# YC3122 register map
Series: ARMCM0; File version: 1.0
CPU: CM0 r1p0, little endian, no MPU, no FPU, 8 interrupt priority bits
Registers are 32-bit, read-write, reset 0x0 unless marked. A register's access mark holds for its fields unless they carry their own. Offsets are from the block's base; [hi:lo] are bit positions; {n}, {i} and the like mark numbered series; 'fields as' and 'values as' point back to an identical list.

## MISO7811
Base 0x000F8F00; alternate view of MDMA_7811
0x00 BASE_ADDR_T1
  [19:0] ISO_BASE_ADDR — Character write base add ress for track 1
0x04 BASE_ADDR_T2
  [19:0] ISO_BASE_ADDR — Character write base add ress for track 2
0x08 BASE_ADDR_T3
  [19:0] ISO_BASE_ADDR — Character write base add ress for track 3
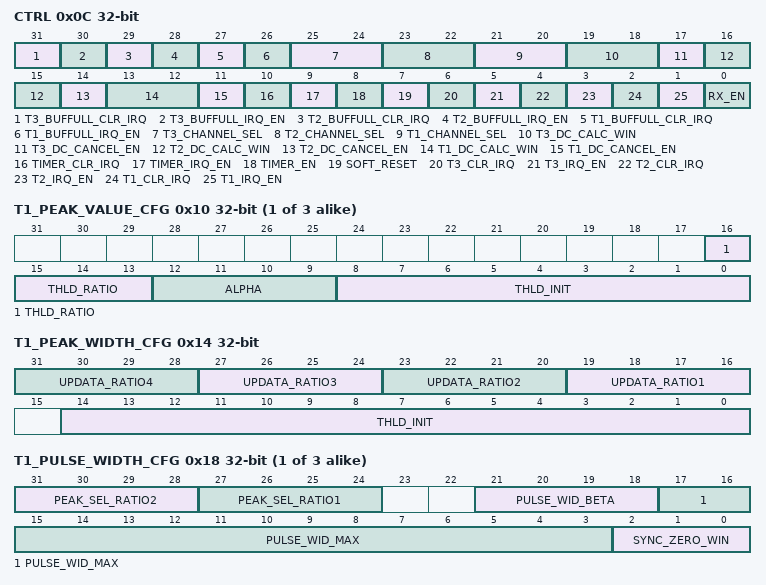
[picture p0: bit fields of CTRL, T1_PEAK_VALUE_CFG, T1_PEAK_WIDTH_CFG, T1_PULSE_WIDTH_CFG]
0x0C CTRL
  [31] T3_BUFFULL_CLR_IRQ — Clear 7811 track 3 buffe r full interrupt
  [30] T3_BUFFULL_IRQ_EN — 7811 track 3 buffer full interrupt enable
  [29] T2_BUFFULL_CLR_IRQ — Clear 7811 track 2 buffe r full interrupt
  [28] T2_BUFFULL_IRQ_EN — 7811 track 2 buffer full interrupt enable
  [27] T1_BUFFULL_CLR_IRQ — Clear 7811 track 1 buffe r full interrupt
  [26] T1_BUFFULL_IRQ_EN — 7811 track 1 buffer full interrupt enable
  [25:24] T3_CHANNEL_SEL — Channel select signal fo r track 3
  [23:22] T2_CHANNEL_SEL — Channel select signal fo r track 2
  [21:20] T1_CHANNEL_SEL — Channel select signal fo r track 1
  [19:18] T3_DC_CALC_WIN — DC calculation window co nfiguration for track 3
  [17] T3_DC_CANCEL_EN — Enable DC cancellation f or track 3
  [16:15] T2_DC_CALC_WIN — DC calculation window co nfiguration for track 2
  [14] T2_DC_CANCEL_EN — Enable DC cancellation f or track 2
  [13:12] T1_DC_CALC_WIN — DC calculation window co nfiguration for track 1
  [11] T1_DC_CANCEL_EN — Enable DC cancellation f or track 1
  [10] TIMER_CLR_IRQ — Clear 7811 timer interru pt
  [9] TIMER_IRQ_EN — 7811 timer interrupt ena ble
  [8] TIMER_EN — Timer enable
  [7] SOFT_RESET — soft reset for AHB bus c ontrol
  [6] T3_CLR_IRQ — Clear 7811 track 3 inter rupt
  [5] T3_IRQ_EN — 7811 track 3 interrupt enable
  [4] T2_CLR_IRQ — Clear 7811 track 2 inter rupt
  [3] T2_IRQ_EN — 7811 track 2 interrupt enable
  [2] T1_CLR_IRQ — Clear 7811 track 1 inter rupt
  [1] T1_IRQ_EN — 7811 track 1 interrupt enable
  [0] RX_EN — 7811 decoder enable
{0x0+0x10*i} T{i}_PEAK_VALUE_CFG (i=1..3)
  [16:13] THLD_RATIO — Peak value threshold rat io
  [12:9] ALPHA — Coefficient for peak val ue update IIR filter
  [8:0] THLD_INIT — Initial peak value thres hold
0x14 T1_PEAK_WIDTH_CFG
  [4n+15:4n+12] UPDATA_RATIO{n} (n=1..4) — Pulse width update ratio. {n}
  [14:0] THLD_INIT — Initial peak value thres hold
{0x8+0x10*i} T{i}_PULSE_WIDTH_CFG (i=1..3)
  [31:28] PEAK_SEL_RATIO2 — Pulse width thld ratio2 for peak select
  [27:24] PEAK_SEL_RATIO1 — Pulse width thld ratio1 for peak select
  [21:18] PULSE_WID_BETA — Coefficient for pulse wi dth threshold IIR filter
  [17:3] PULSE_WID_MAX — Maximum pulse width valu e
  [2:0] SYNC_ZERO_WIN — Synchronized zero judgem ent window
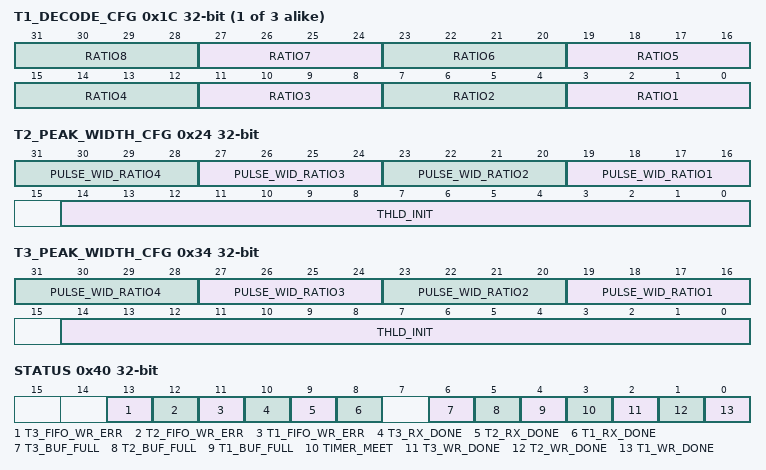
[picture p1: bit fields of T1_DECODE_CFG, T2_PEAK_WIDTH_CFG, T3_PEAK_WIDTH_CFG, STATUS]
{0xC+0x10*i} T{i}_DECODE_CFG (i=1..3)
  [4n-1:4n-4] RATIO{n} (n=1..8) — Pulse width threshold{n} f or decode
0x24 T2_PEAK_WIDTH_CFG
  [4n+15:4n+12] PULSE_WID_RATIO{n} (n=1..4) — Pulse width update ratio. {n}
  [14:0] THLD_INIT — Initial peak value thres hold
0x34 T3_PEAK_WIDTH_CFG
  fields as T2_PEAK_WIDTH_CFG
0x40 STATUS
  [13] T3_FIFO_WR_ERR ro — Track 3 fifo write error
  [12] T2_FIFO_WR_ERR ro — Track 2 fifo write error
  [11] T1_FIFO_WR_ERR ro — Track 1 fifo write error
  [10] T3_RX_DONE ro — 7811 decoder rx done sig nal for track3
  [9] T2_RX_DONE ro — 7811 decoder rx done sig nal for track2
  [8] T1_RX_DONE ro — 7811 decoder rx done sig nal for track1
  [6] T3_BUF_FULL ro — Track 3 buffer full
  [5] T2_BUF_FULL ro — Track 2 buffer full
  [4] T1_BUF_FULL ro — Track 1 buffer full
  [3] TIMER_MEET ro — Timer meet limit
  [2] T3_WR_DONE ro — Shared memory write done signal for track3
  [1] T2_WR_DONE ro — Shared memory write done signal for track2
  [0] T1_WR_DONE ro — Shared memory write done signal for track1
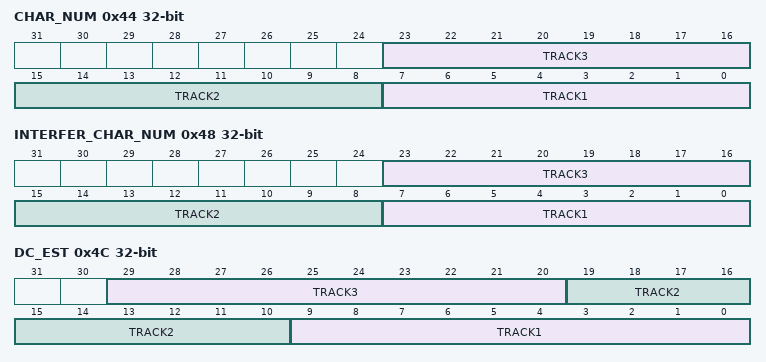
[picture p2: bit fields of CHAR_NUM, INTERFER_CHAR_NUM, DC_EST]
0x44 CHAR_NUM
  [23:16] TRACK3 ro — Track 3 character number
  [15:8] TRACK2 ro — Track 2 character number
  [7:0] TRACK1 ro — Track 1 character number
0x48 INTERFER_CHAR_NUM
  [23:16] TRACK3 ro — Track 3 interference cha racter number
  [15:8] TRACK2 ro — Track 2 interference cha racter number
  [7:0] TRACK1 ro — Track 1 interference cha racter number
0x4C DC_EST
  [29:20] TRACK3 ro — Track 3 dc value for dco c
  [19:10] TRACK2 ro — Track 2 dc value for dco c
  [9:0] TRACK1 ro — Track 1 dc value for dco c
{0x4C+4i} END_ADDR_T{i} (i=1..3)
  [19:0] ISO_END_ADDR — Character write end addr ess for track {i}
0x5C TIMER_LIMIT
  [31:0] LIMIT — Timer limit for interrup t
